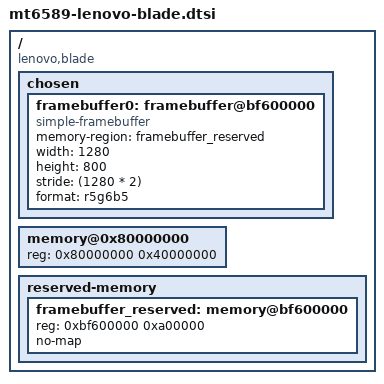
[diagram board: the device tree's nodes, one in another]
// SPDX-License-Identifier: (GPL-2.0-only OR BSD-2-Clause)
/*
 * Copyright (c) 2026 Akari Tsuyukusa <akkun11.open@gmail.com>
 */

/dts-v1/;
#include "mt6589.dtsi"

/ {
	compatible = "lenovo,blade", "mediatek,mt6589";

	chosen {
		framebuffer0: framebuffer@bf600000 {
			compatible = "simple-framebuffer";
			memory-region = <&framebuffer_reserved>;
			width = <1280>;
			height = <800>;
			stride = <(1280 * 2)>;
			format = "r5g6b5";
		};
	};

	memory@0x80000000 {
		device_type = "memory";
		reg = <0x80000000 0x40000000>;
	};

	reserved-memory {
		#address-cells = <1>;
		#size-cells = <1>;

		ranges;

		framebuffer_reserved: memory@bf600000{
			reg = <0xbf600000 0xa00000>;
			no-map;
		};
	};
};
